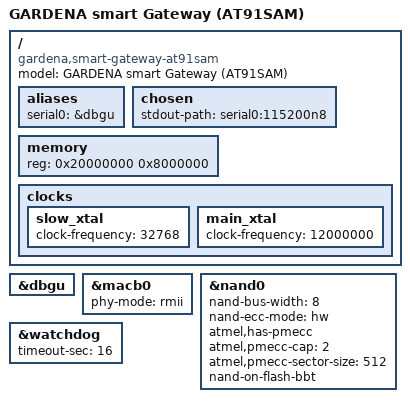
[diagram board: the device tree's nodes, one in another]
// SPDX-License-Identifier: GPL-2.0+
/*
 * Device Tree file for the GARDENA smart Gateway (AT91SAM)
 *
 *  Copyright (C) 2012 Atmel,
 *                2012 Nicolas Ferre <nicolas.ferre@atmel.com>
 */

/dts-v1/;

#include "at91sam9g25.dtsi"

/ {
	model = "GARDENA smart Gateway (AT91SAM)";
	compatible = "gardena,smart-gateway-at91sam", "atmel,at91sam9";

	aliases {
		serial0 = &dbgu;
	};

	chosen {
		stdout-path = "serial0:115200n8";
	};

	memory {
		reg = <0x20000000 0x8000000>;
	};

	clocks {
		slow_xtal {
			clock-frequency = <32768>;
		};

		main_xtal {
			clock-frequency = <12000000>;
		};
	};
};

&dbgu {
	status = "okay";
};

&macb0 {
	phy-mode = "rmii";
	status = "okay";
};

&nand0 {
	nand-bus-width = <8>;
	nand-ecc-mode = "hw";
	atmel,has-pmecc;	/* Enable PMECC */
	atmel,pmecc-cap = <2>;
	atmel,pmecc-sector-size = <512>;
	nand-on-flash-bbt;
	status = "okay";
};

&watchdog {
	status = "okay";
	timeout-sec = <16>;
};
